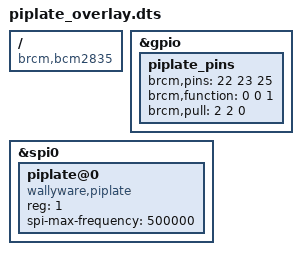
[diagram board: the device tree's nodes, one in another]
/dts-v1/;
/plugin/;

/ {
	compatible = "brcm,bcm2835", "brcm,bcm2708", "brcm,bcm2709", "brcm, bcm2710";

	fragment@0 {
		target = <&gpio>;
		__overlay__ {
			piplate_pins: piplate_pins {
				brcm,pins = <22 23 25>;
				brcm,function = <0 0 1>;
				brcm,pull = <2 2 0>;
			};
		};
	};	

	fragment@1 {
		target = <&spi0>;
		__overlay__ {
			#address-cells = <1>;
			#size-cells = <0>;			
			piplate@0{
				compatible = "wallyware,piplate";
				reg = <1>;
				spi-max-frequency = <500000>;
				status = "okay";
			};
		};
	};
};
